# STM32G031C4T6 register map
File version: 1.0
STM32G031C4T6,STM32G031C4U6,STM32G031C6T6,STM32G031C6U6,STM32G031C8T6,STM32G031C8T7,STM32G031C8U6,STM32G031C8U7,STM32G031F4P3,STM32G031F4P6,STM32G031F4P7,STM32G031F6P6,STM32G031F6P7,STM32G031F8P6,STM32G031G4U6,STM32G031G6U3,STM32G031G6U6,STM32G031G6U7,STM32G031G8U3,STM32G031G8U6,STM32G031G8U7,STM32G031J4M6,STM32G031J6M3,STM32G031J6M6,STM32G031J6M7,STM32G031K4T3,STM32G031K4T6,STM32G031K4T7,STM32G031K4U3,STM32G031K4U6,STM32G031K4U7,STM32G031K6T6,STM32G031K6U6,STM32G031K8T3,STM32G031K8T6,STM32G031K8T7,STM32G031K8U3,STM32G031K8U6,STM32G031K8U7,STM32G031Y8Y6,STM32G041C6T6,STM32G041C6U6,STM32G041C8T6,STM32G041C8U6,STM32G041F6P6,STM32G041F8P6,STM32G041G6U6,STM32G041G8U6,STM32G041J6M6,STM32G041K6T6,STM32G041K6U6,STM32G041K8T6,STM32G041K8U6,STM32G041Y8Y6,STM32G051C6T6,STM32G051C6U6,STM32G051C8T6,STM32G051C8U6,STM32G051F6P6,STM32G051F8P6,STM32G051F8Y6,STM32G051G6U6,STM32G051G8U3,STM32G051G8U6,STM32G051G8U7,STM32G051K6T6,STM32G051K6T7,STM32G051K6U6,STM32G051K6U7,STM32G051K8T6,STM32G051K8T7,STM32G051K8U6,STM32G051K8U7,STM32G061C6T6,STM32G061C6U6,STM32G061C8T6,STM32G061C8U6,STM32G061F6P6,STM32G061F8P6,STM32G061F8Y6,STM32G061G6U6,STM32G061G8U6,STM32G061K6T6,STM32G061K6U6,STM32G061K8T6,STM32G061K8U6,STM32G071C6T6,STM32G071C6U3,STM32G071C6U6,STM32G071C6U7,STM32G071C8T3,STM32G071C8T6,STM32G071C8T7,STM32G071C8U3,STM32G071C8U6,STM32G071C8U7,STM32G071CBT3,STM32G071CBT6,STM32G071CBT7,STM32G071CBU3,STM32G071CBU6,STM32G071CBU7,STM32G071EBY6,STM32G071G6U3,STM32G071G6U6,STM32G071G6U7,STM32G071G8U6,ST
Registers are 32-bit, access not given, reset 0x0 unless marked. A register's access mark holds for its fields unless they carry their own. Offsets are from the block's base; lines under a group give offsets from that group; [hi:lo] are bit positions; {n}, {i} and the like mark numbered series; 'fields as' and 'values as' point back to an identical list; <NAME> marks a mode.

## Memory map
0x40000000 TIM2
0x40000400 TIM3
0x40000800 TIM4
0x40001000 TIM6
0x40001400 TIM7
0x40002000 TIM14
0x40002800 RTC
0x40002C00 WWDG
0x40003000 IWDG
0x40003800 SPI2
0x40003C00 SPI3
0x40004400 USART2
0x40004800 USART3
0x40004C00 USART4
0x40005000 USART5
0x40005400 I2C1
0x40005800 I2C2
0x40005C00 USB
0x40006400 FDCAN1
0x40006800 FDCAN2
0x40006C00 CRS
0x40007000 PWR
0x40007400 DAC
0x40007800 CEC
0x40007C00 LPTIM1
0x40008000 LPUART1
0x40008400 LPUART2
0x40008800 I2C3
0x40009400 LPTIM2
0x4000A000 UCPD1
0x4000A400 UCPD2
0x4000B000 TAMP
0x40010000 SYSCFG
0x40010030 VREFBUF
0x40010080 ITLINE
0x40010200 COMP
0x40012400 ADC
0x40012C00 TIM1
0x40013000 SPI1
0x40013800 USART1
0x40013C00 USART6
0x40014000 TIM15
0x40014400 TIM16
0x40014800 TIM17
0x40015800 DBG
0x40020000 DMA1
0x40020400 DMA2
0x40020800 DMAMUX
0x40021000 RCC
0x40021800 EXTI
0x40022000 FLASH
0x40023000 CRC
0x40025000 RNG
0x40026000 AES
0x50000000 GPIOA
0x50000400 GPIOB
0x50000800 GPIOC
0x50000C00 GPIOD
0x50001000 GPIOE
0x50001400 GPIOF

## TIM2
Base 0x40000000
Same registers: TIM3 0x40000400, TIM4 0x40000800
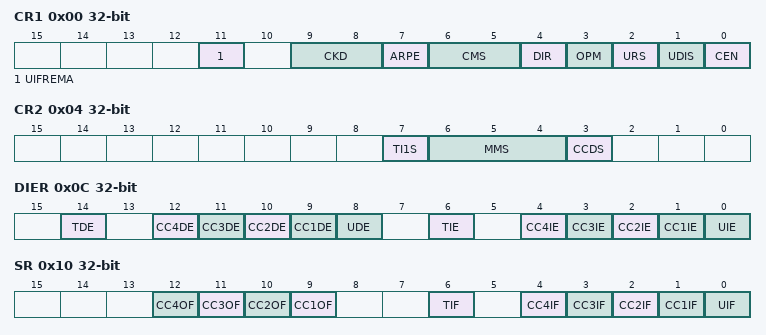
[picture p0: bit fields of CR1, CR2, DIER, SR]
0x00 CR1
  [11] UIFREMA, [9:8] CKD, [7] ARPE, [6:5] CMS, [4] DIR, [3] OPM, [2] URS, [1] UDIS, [0] CEN
0x04 CR2
  [7] TI1S, [6:4] MMS, [3] CCDS
0x08 SMCR
  [15] ETP, [14] ECE, [13:12] ETPS, [11:8] ETF, [7] MSM, [21:4] TS, [16:0] SMS
0x0C DIER
  [14] TDE, [n+8] CC{n}DE (n=1..4), [8] UDE, [6] TIE, [n] CC{n}IE (n=1..4), [0] UIE
0x10 SR
  [n+8] CC{n}OF (n=1..4), [6] TIF, [n] CC{n}IF (n=1..4), [0] UIF
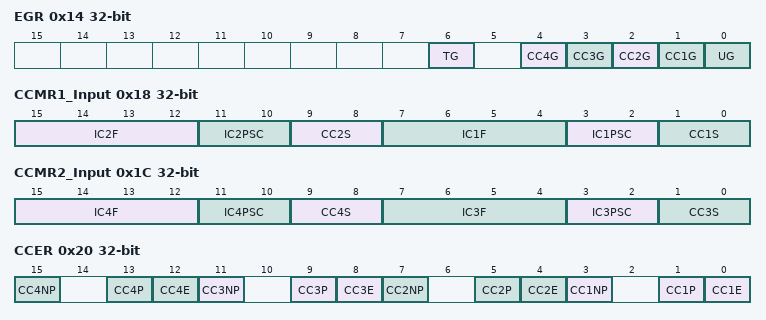
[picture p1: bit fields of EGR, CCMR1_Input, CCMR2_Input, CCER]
0x14 EGR
  [6] TG, [n] CC{n}G (n=1..4), [0] UG
0x18 CCMR1_Output
  [15] OC2CE, [24:12] OC2M, [11] OC2PE, [10] OC2FE, [9:8] CC2S, [7] OC1CE, [16:4] OC1M, [3] OC1PE, [2] OC1FE, [1:0] CC1S
0x18 CCMR1_Input
  [15:12] IC2F, [11:10] IC2PSC, [9:8] CC2S, [7:4] IC1F, [3:2] IC1PSC, [1:0] CC1S
0x1C CCMR2_Output
  [15] O24CE, [24:12] OC4M, [11] OC4PE, [10] OC4FE, [9:8] CC4S, [7] OC3CE, [16:4] OC3M, [3] OC3PE, [2] OC3FE, [1:0] CC3S
0x1C CCMR2_Input
  [15:12] IC4F, [11:10] IC4PSC, [9:8] CC4S, [7:4] IC3F, [3:2] IC3PSC, [1:0] CC3S
0x20 CCER
  [4n-1] CC{n}NP (n=1..4), [4n-3] CC{n}P (n=1..4), [4n-4] CC{n}E (n=1..4)
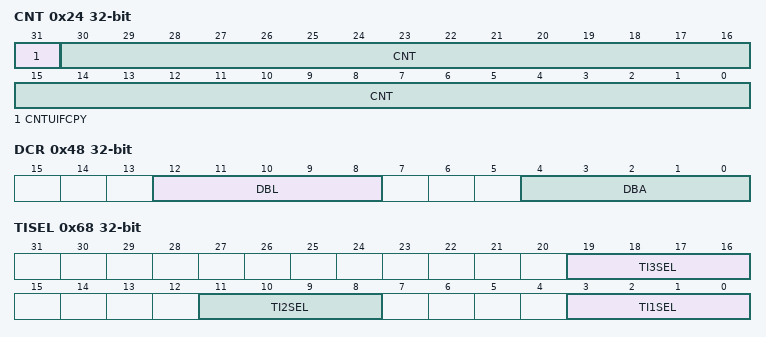
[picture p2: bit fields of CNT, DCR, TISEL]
0x24 CNT
  [31] CNTUIFCPY, [30:0] CNT
0x28 PSC
  [15:0] PSC
0x2C ARR
{0x30+4i} CCR{i} (i=1..4)
0x48 DCR
  [12:8] DBL, [4:0] DBA
0x4C DMAR
  [15:0] DMAB
0x50 OR1
  [1:0] OCREF_CLR
0x60 AF1
  [17:14] ETRSEL
0x68 TISEL
  [19:16] TI3SEL, [11:8] TI2SEL, [3:0] TI1SEL
